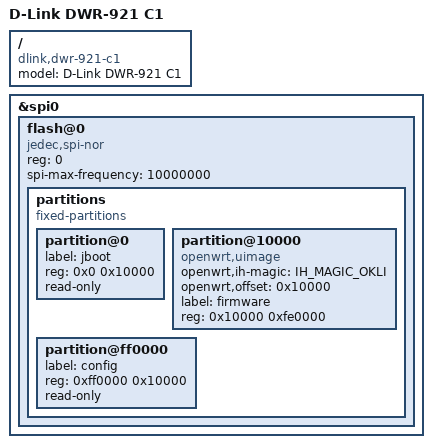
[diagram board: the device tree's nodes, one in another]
// SPDX-License-Identifier: GPL-2.0-or-later OR MIT

#include "mt7620n_dlink_dwr-921.dtsi"

#include <dt-bindings/mtd/partitions/uimage.h>

/ {
	compatible = "dlink,dwr-921-c1", "ralink,mt7620n-soc";
	model = "D-Link DWR-921 C1";
};

&spi0 {
	status = "okay";

	flash@0 {
		compatible = "jedec,spi-nor";
		reg = <0>;
		spi-max-frequency = <10000000>;

		partitions {
			compatible = "fixed-partitions";
			#address-cells = <1>;
			#size-cells = <1>;

			partition@0 {
				label = "jboot";
				reg = <0x0 0x10000>;
				read-only;
			};

			partition@10000 {
				compatible = "openwrt,uimage", "denx,uimage";
				openwrt,ih-magic = <IH_MAGIC_OKLI>;
				openwrt,offset = <0x10000>;
				label = "firmware";
				reg = <0x10000 0xfe0000>;
			};

			partition@ff0000 {
				label = "config";
				reg = <0xff0000 0x10000>;
				read-only;
			};
		};
	};
};
